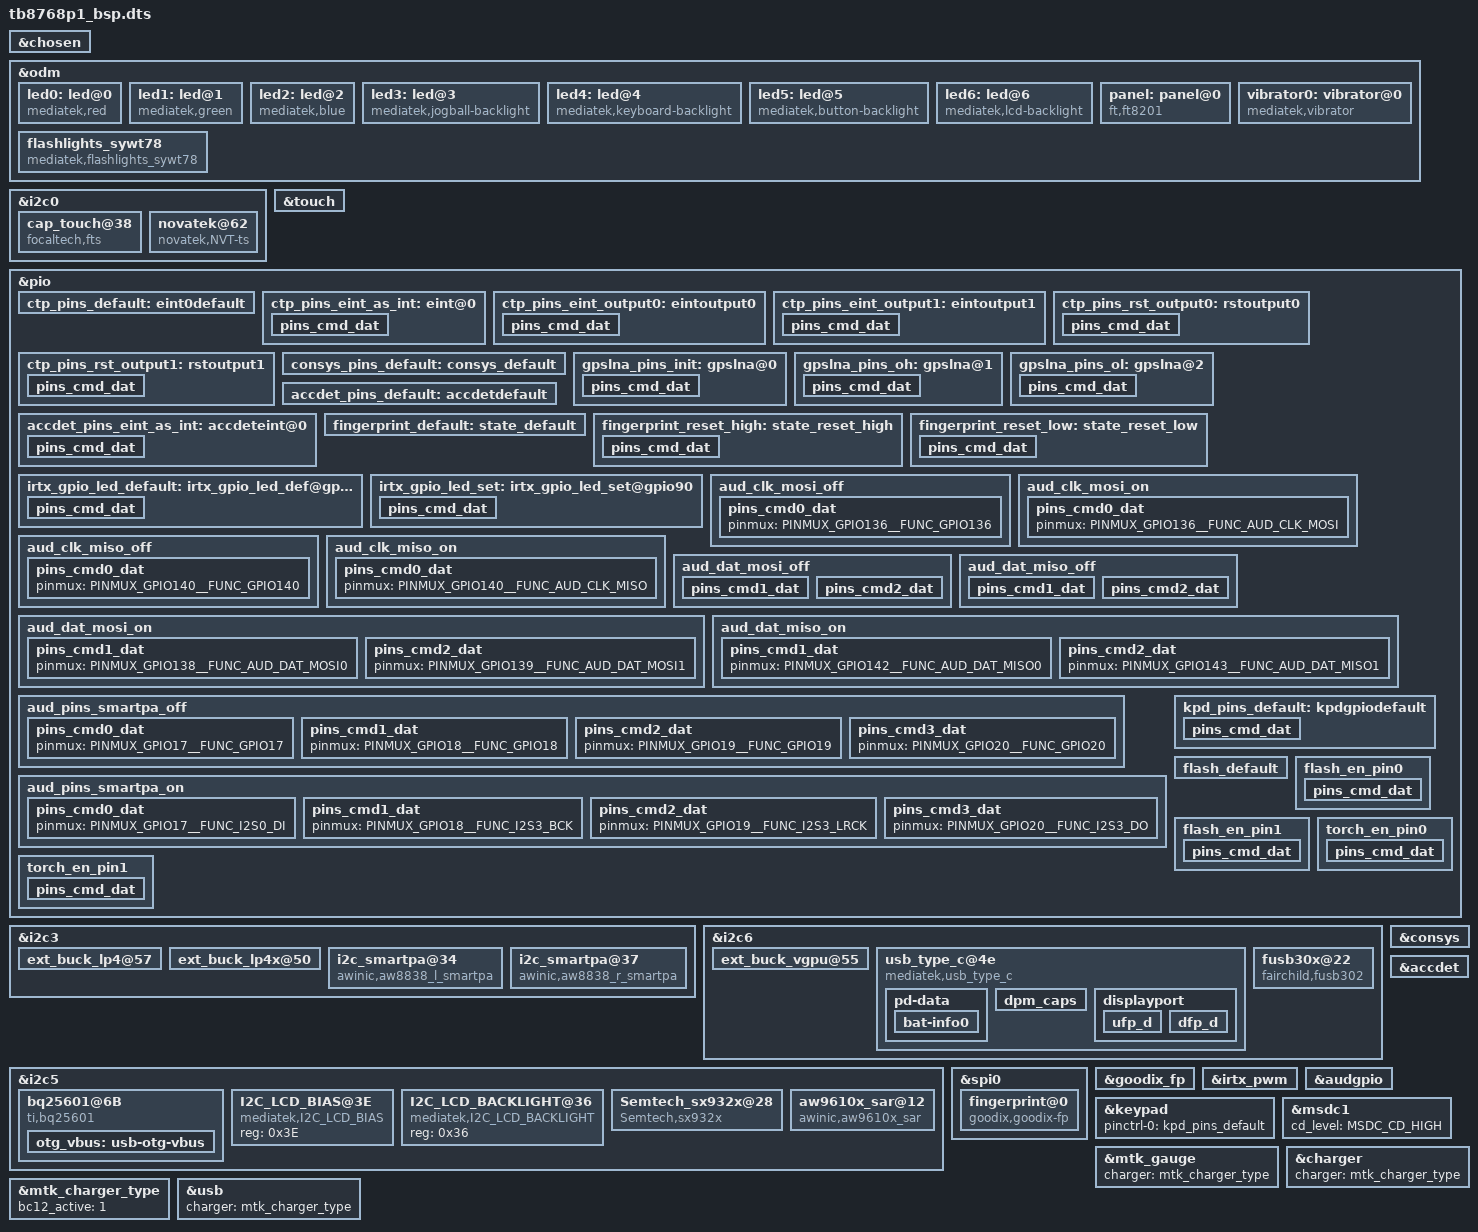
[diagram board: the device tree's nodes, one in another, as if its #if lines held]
// SPDX-License-Identifier: GPL-2.0+
/*
 * Copyright (c) 2019 MediaTek Inc.
 *
 */

#include <dt-bindings/interrupt-controller/arm-gic.h>
#include <dt-bindings/interrupt-controller/irq.h>
#include <dt-bindings/pinctrl/mt6765-pinfunc.h>
#include <dt-bindings/clock/mt6765-clk.h>
#include <dt-bindings/mmc/mt6765-msdc.h>

/dts-v1/;
/plugin/;

/* chosen */
&chosen {

	/* fpga may has no lk, we need to specify display info here */
	/* fb buffer is reserved using this dts by memory node above */
	atag,videolfb-fb_base_h = <0x0>;
	atag,videolfb-fb_base_l = <0x5e605000>;
	atag,videolfb-islcmfound = <1>;
	/* because no lk, so lcm is not inited */
	atag,videolfb-islcm_inited = <0>;
	atag,videolfb-fps= <6000>;
	atag,videolfb-vramSize= <0x017bb000>;
	atag,videolfb-lcmname= "ft8201_wxga_vdo_incell_boe";
};

&odm {
	led0:led@0 {
		compatible = "mediatek,red";
		led_mode = <0>;
		data = <1>;
		pwm_config = <0 0 0 0 0>;
	};
	led1:led@1 {
		compatible = "mediatek,green";
		led_mode = <0>;
		data = <1>;
		pwm_config = <0 0 0 0 0>;
	};
	led2:led@2 {
		compatible = "mediatek,blue";
		led_mode = <0>;
		data = <1>;
		pwm_config = <0 0 0 0 0>;
	};
	led3:led@3 {
		compatible = "mediatek,jogball-backlight";
		led_mode = <0>;
		data = <1>;
		pwm_config = <0 0 0 0 0>;
	};
	led4:led@4 {
		compatible = "mediatek,keyboard-backlight";
		led_mode = <0>;
		data = <1>;
		pwm_config = <0 0 0 0 0>;
	};
	led5:led@5 {
		compatible = "mediatek,button-backlight";
		led_mode = <0>;
		data = <1>;
		pwm_config = <0 0 0 0 0>;
	};
	led6:led@6 {
		compatible = "mediatek,lcd-backlight";
		led_mode = <4>;
		data = <1>;
		pwm_config = <0 3 0 0 0>;
	};
	panel: panel@0 {
		compatible = "ft,ft8201";
		gpio_lcd_rst = <&pio 45 0>;
		gpio_lcd_bl_en = <&pio 154 0>;
		gpio_lcd_bias_enp = <&pio 168 0>;
		gpio_lcd_bias_enn = <&pio 173 0>;
		gpio_tp_rst = <&pio 174 0>;
		status = "okay";
	};
	vibrator0:vibrator@0 {
		compatible = "mediatek,vibrator";
		vib_timer = <25>;
		vib_limit = <9>;
		vib_vol= <9>;
	};
};

/*
&pio {
	lcd_disp_pwm: lcd_disp_pwm {
		pins_cmd_dat {
			pinmux = <PINMUX_GPIO43__FUNC_DISP_PWM>;
		};
	};

	lcd_disp_pwm_gpio: lcd_disp_pwm_gpio {
		pins_cmd_dat {
			pinmux = <PINMUX_GPIO43__FUNC_GPIO43>;
			output-low;
		};
	};
};
*/

&i2c0 {
	cap_touch@38 {
		compatible = "focaltech,fts";
		reg = < 0x38 > ;
		status = "okay" ;
		focaltech,display-coords =  <0 0 800 1280>;
		interrupt-parent = <&pio>;
		interrupts = <0 0x2>;
		focaltech,reset-gpio = <&pio 174 0x01>; 
		focaltech,irq-gpio = <&pio 0 0x02>;
		focaltech,max-touch-number = <10>;
		
	};
	
	novatek@62 {
		compatible = "novatek,NVT-ts" ;
		reg = < 0x62 > ;
		novatek,irq-gpio = <&pio 0 0x2001>;
		status = "okay" ;
	};
};
/* TOUCH start */
&touch {
	tpd-resolution = <800 1280>;
	use-tpd-button = <0>;
	tpd-key-num = <3>;
	//tpd-key-local= <139 172 158 0>;
	//tpd-key-dim-local = <90 883 100 40 230
	//			 883 100 40 370 883 100 40 0 0 0 0>;
	tpd-max-touch-num = <10>;
	tpd-filter-enable = <0>;
	tpd-filter-pixel-density = <106>;
	tpd-filter-custom-prameters = <0 0 0 0 0 0 0 0 0 0 0 0>;
	tpd-filter-custom-speed = <0 0 0>;
	pinctrl-names = "default", "state_eint_as_int", "state_eint_output0",
		"state_eint_output1", "state_rst_output0", "state_rst_output1";
	pinctrl-0 = <&ctp_pins_default>;
	pinctrl-1 = <&ctp_pins_eint_as_int>;
	pinctrl-2 = <&ctp_pins_eint_output0>;
	pinctrl-3 = <&ctp_pins_eint_output1>;
	pinctrl-4 = <&ctp_pins_rst_output0>;
	pinctrl-5 = <&ctp_pins_rst_output1>;
	status = "okay";
};
&pio {
	ctp_pins_default: eint0default {
	};
	ctp_pins_eint_as_int: eint@0 {
		pins_cmd_dat {
			pinmux = <PINMUX_GPIO0__FUNC_GPIO0>;
			slew-rate = <0>;
			bias-disable;
		};
	};
	ctp_pins_eint_output0: eintoutput0 {
		pins_cmd_dat {
			pinmux = <PINMUX_GPIO0__FUNC_GPIO0>;
			slew-rate = <1>;
			output-low;
		};
	};
	ctp_pins_eint_output1: eintoutput1 {
		pins_cmd_dat {
			pinmux = <PINMUX_GPIO0__FUNC_GPIO0>;
			slew-rate = <1>;
			output-high;
		};
	};
	ctp_pins_rst_output0: rstoutput0 {
		pins_cmd_dat {
			pinmux = <PINMUX_GPIO174__FUNC_GPIO174>;
			slew-rate = <1>;
			output-low;
		};
	};
	ctp_pins_rst_output1: rstoutput1 {
		pins_cmd_dat {
			pinmux = <PINMUX_GPIO174__FUNC_GPIO174>;
			slew-rate = <1>;
			output-high;
		};
	};
};
/* TOUCH end */

&i2c3 {
	ext_buck_lp4@57 {
		regulator-name ="ext_buck_vdd2";
		regulator-min-microvolt = <300000>;
		regulator-max-microvolt = <1300000>;
		vsel_pin = <0>;
	};

	ext_buck_lp4x@50 {
		regulator-name ="ext_buck_vddq";
		regulator-min-microvolt = <300000>;
		regulator-max-microvolt = <1300000>;
		vsel_pin = <1>;
	};
	i2c_smartpa@34 {
		compatible = "awinic,aw8838_l_smartpa";
		reg = <0x34>;
		reset-gpio = <&pio 153 0>;
		status = "okay";
	};
	i2c_smartpa@37 {
		compatible = "awinic,aw8838_r_smartpa";
		reg = <0x37>;
		reset-gpio = <&pio 150 0>;
		status = "okay";
	};
};

&i2c6 {
	ext_buck_vgpu@55 {
		regulator-name ="ext_buck_vgpu";
		regulator-min-microvolt = <300000>;
		regulator-max-microvolt = <1300000>;
		vsel_pin = <2>;
	};

	/*aw87519@58 {
		compatible = "awinic,aw87519_left";
		reg = <0x58>;
		reset-gpio = <&pio 174 0>;
		status = "okay";
	};*/
	usb_type_c@4e {
		compatible = "mediatek,usb_type_c";
		reg = <0x4e>;
		charger = <&mtk_charger_type>;
		tcpc-dual,supported_modes = <0>; /* 0: dfp/ufp, */
						 /* 1: dfp, 2: ufp */
		rt-tcpc,name = "type_c_port0"; /* tcpc_device's name */
		rt-tcpc,role_def = <4>; /* 0: SNK Only, 1: SRC Only, 2: DRP, */
					/* 3: Try.SRC, 4: Try.SNK */
		rt-tcpc,rp_level = <0>; /* 0: Default, 1: 1.5, 2: 3.0 */
		rt-tcpc,vconn_supply  = <1>;  /* 0: Never, 1: Always, */
					      /* 2: EMarkOnly, 3: StartOnly */
#if (CONFIG_MTK_GAUGE_VERSION == 30)
		rt-tcpc,notifier_supply_num = <3>;
#else
		rt-tcpc,notifier_supply_num = <2>;
#endif
		rt1711pd,intr_gpio = <&pio 8 0x0>;
		rt1711pd,intr_gpio_num = <8>;
		pd-data {
			pd,vid = <0x29cf>;
			pd,pid = <0x1711>;
			pd,source-cap-ext = <0x171129cf 0x00000000 0x00000000
					     0x00000000 0x00000000 0x02000000>;
			pd,mfrs = "RichtekTCPC";

			/*
			 *	VSAFE5V = 0, MAX_POWER = 1, CUSTOM = 2,
			 *	MAX_POWER_LV = 0x21, MAX_POWER_LVIC = 0x31
			 *	MAX_POWER_HV = 0x41, MAX_POWER_HVIC = 0x51
			 */
			pd,charging_policy= <0x31>;

			/*
			 * Fixed 5V, 500 mA <0x00019032>
			 * Fixed 5V, 1A <0x00019064>
			 * Fixed 5V, 2A <0x000190c8>
			 * Fixed 5V, 3A <0x0001912c>
			 * Fixed 9V, 500 mA <0x0002d032>
			 * Fixed 9V, 1A <0x0002d064>
			 * Fixed 9V, 2A <0x0002d0c8>
			 * Fixed 9V, 3A <0x0002d12c>
			 * Variable 5-9V, 1A <0x8642d064>
			 * Variable 5-9V, 2A <0x8642d0c8>
			 * Variable 5-9V, 3A <0x8642d12c>
			 * PPS 3V~5.9V, 3A <0xC0761E3C>
			 */
			pd,source-pdo-size = <1>;
			pd,source-pdo-data = <0x00019032>;
			pd,sink-pdo-size = <1>;
			pd,sink-pdo-data = <0x000190c8>;

			/*
			 * No DP, host + device
			 *	pd,id-vdo-size = <3>;
			 *	pd,id-vdo-data = <0xd10029cf 0x0 0x17110000>;
			 * With DP
			 *	pd,id-vdo-size = <3>;
			 *	pd,id-vdo-data = <0xd60029cf 0x0 0x17110000
			 */

			pd,id-vdo-size = <3>;
			pd,id-vdo-data = <0xd10029cf 0x0 0x17110000>;

			bat,nr = <1>;
			pd,country_nr = <0>;

			bat-info0 {
				bat,vid = <0x29cf>;
				bat,pid = <0x1711>;
				bat,mfrs = "bat1";
				bat,design_cap = <3000>;
			};

			//bat-info1 {
			//	bat,vid = <0x8abc>;
			//	bat,pid = <0x5234>;
			//	bat,mfrs = "bat2";
			//	bat,design_cap = <4000>;
			//};

			//country0 {
			//	pd,country_code = <0x5457>;
			//	pd,country_len = <2>; /* max len = 26 */
			//	pd,country_data = <0xff 0xff>;
			//};

			//country1 {
			//	pd,country_code = <0x5553>;
			//	pd,country_len = <3>; /* max len = 26 */
			//	pd,country_data = <0xf1 0xf2 0xf3>;
			//};
		};
		dpm_caps {
			local_dr_power;
			local_dr_data;
			//local_ext_power;
			local_usb_comm;
			//local_usb_suspend;
			//local_high_cap;
			//local_give_back;
			local_no_suspend;
			local_vconn_supply;

			//attemp_discover_cable_dfp;
			attemp_enter_dp_mode;
			attemp_discover_cable;
			attemp_discover_id;

			/* 0: disable, 1: prefer_snk, 2: prefer_src */
			pr_check = <0>;
			//pr_reject_as_source;
			//pr_reject_as_sink;
			//pr_check_gp_source;
			//pr_check_gp_sink;

			/* 0: disable, 1: prefer_ufp, 2: prefer_dfp */
			dr_check = <0>;
			//dr_reject_as_dfp;
			//dr_reject_as_ufp;
		};
		displayport {
			/* connection type = "both", "ufp_d", "dfp_d" */
			1st_connection = "dfp_d";
			2nd_connection = "dfp_d";
			signal,dp_v13;
			//signal,dp_gen2;
			usbr20_not_used;
			typec,receptacle;
			ufp_d {
				//pin_assignment,mode_a;
				//pin_assignment,mode_b;
				//pin_assignment,mode_c;
				//pin_assignment,mode_d;
				//pin_assignment,mode_e;
			};
			dfp_d {
				/* Only support mode C & D */
				//pin_assignment,mode_a;
				//pin_assignment,mode_b;
				pin_assignment,mode_c;
				pin_assignment,mode_d;
				pin_assignment,mode_e;
				pin_assignment,mode_f;
			};
		};
	};
	fusb30x@22 {
		status = "ok";
		compatible = "fairchild,fusb302";
		reg = <0x22>;
		interrupt-parent = <&pio>;
		interrupts = <8 0x2>;
		fairchild,int_n = <&pio 8 0>;
	};
};
/* TOUCH start */
/*
&touch {
	tpd-resolution = <1200 1920>;
	use-tpd-button = <0>;
	tpd-key-num = <3>;
	tpd-key-local= <139 172 158 0>;
	tpd-key-dim-local = <90 883 100 40 230
				 883 100 40 370 883 100 40 0 0 0 0>;
	tpd-max-touch-num = <10>;
	tpd-filter-enable = <0>;
	tpd-filter-pixel-density = <106>;
	tpd-filter-custom-prameters = <0 0 0 0 0 0 0 0 0 0 0 0>;
	tpd-filter-custom-speed = <0 0 0>;
	pinctrl-names = "default", "state_eint_as_int", "state_eint_output0",
		"state_eint_output1", "state_rst_output0", "state_rst_output1";
	pinctrl-0 = <&ctp_pins_default>;
	pinctrl-1 = <&ctp_pins_eint_as_int>;
	pinctrl-2 = <&ctp_pins_eint_output0>;
	pinctrl-3 = <&ctp_pins_eint_output1>;
	pinctrl-4 = <&ctp_pins_rst_output0>;
	pinctrl-5 = <&ctp_pins_rst_output1>;
	status = "okay";
};
&pio {
	ctp_pins_default: eint0default {
	};
	ctp_pins_eint_as_int: eint@0 {
		pins_cmd_dat {
			pinmux = <PINMUX_GPIO10__FUNC_GPIO10>;
			slew-rate = <0>;
			bias-disable;
		};
	};
	ctp_pins_eint_output0: eintoutput0 {
		pins_cmd_dat {
			pinmux = <PINMUX_GPIO10__FUNC_GPIO10>;
			slew-rate = <1>;
			output-low;
		};
	};
	ctp_pins_eint_output1: eintoutput1 {
		pins_cmd_dat {
			pinmux = <PINMUX_GPIO10__FUNC_GPIO10>;
			slew-rate = <1>;
			output-high;
		};
	};
	ctp_pins_rst_output0: rstoutput0 {
		pins_cmd_dat {
			pinmux = <PINMUX_GPIO172__FUNC_GPIO172>;
			slew-rate = <1>;
			output-low;
		};
	};
	ctp_pins_rst_output1: rstoutput1 {
		pins_cmd_dat {
			pinmux = <PINMUX_GPIO172__FUNC_GPIO172>;
			slew-rate = <1>;
			output-high;
		};
	};
};
*/
/* TOUCH end */

&i2c5 {
	bq25601@6B {
		status = "okay";
		compatible = "ti,bq25601";
		reg = <0x6B>;

		charger_name = "primary_chg";

		ti,bq2560x,usb-vlim = <4600>;
		ti,bq2560x,usb-ilim = <500>;
		ti,bq2560x,usb-vreg = <4400>;
		ti,bq2560x,usb-ichg = <500>;
		ti,bq2560x,precharge-current = <256>;
		ti,bq2560x,termination-current = <180>;
		ti,bq2560x,boost-voltage = <4998>;
		ti,bq2560x,boost-current = <1200>;
		ti,bq2560x,enable_term;
		ti,bq2560x,stat-pin-ctrl = <3>;
		ti,bq2560x,vac-ovp-threshold = <6500>;
		ti,bq2560x,otg-discharge-gpio = <&pio 24 0x0>;

		otg_vbus: usb-otg-vbus {
			regulator-compatible = "usb-otg-vbus";
			regulator-name = "usb-otg-vbus";
			regulator-min-microvolt = <5000000>;
			regulator-max-microvolt = <5000000>;
		};
	};
	I2C_LCD_BIAS@3E {
		compatible = "mediatek,I2C_LCD_BIAS" ;
		reg = <0x3E> ;
		status = "okay" ;
	};
	I2C_LCD_BACKLIGHT@36 {
		compatible = "mediatek,I2C_LCD_BACKLIGHT" ;
		reg = <0x36> ;
		status = "okay" ;
	};
	/* LCT_P502 modify by jiangqianwen in 202010 start */
 	Semtech_sx932x@28 {
 		compatible = "Semtech,sx932x";
 		reg = <0x28>;
 		interrupt-parent = <&pio>;
 		interrupts = <9 0>;
 
 		Semtech,nirq-gpio = <&pio 9 0x00>;
 		status = "ok";	/**/
 		Semtech,reg-num = <40>; /* total registers number to initialize*/
        Semtech,reg-init  = /bits/ 8 < 
                                 0x10 0x16
                                 0x11 0x20
                                 0X14 0X00
                                 0X15 0X00
                                 0x20 0x20
                                 0x23 0x00
                                 0x24 0xAF
                                 0x26 0x00
                                 0x27 0xAF
                                 0x28 0x3D /*PH0 to CS0 input*/
                                 0x29 0x37
                                 0x2A 0x1F /*PH2 CS2-input,CS1-dync,CS0-HZ*/
                                 0x2B 0x3F
                                 0x2C 0x12
                                 0x2D 0x0B
                                 0x30 0x13
                                 0x31 0x13
                                 0x32 0x20
                                 0x33 0x20
                                 0x34 0x0C
                                 0x35 0x00
                                 0x36 0x0F
                                 0x37 0x16
                                 0x40 0x00
                                 0x41 0x00
                                 0x42 0x11
                                 0x43 0x04
                                 0x44 0x00
                                 0x45 0x05
                                 0x46 0x00
                                 0x47 0x00
                                 0x48 0x00
                                 0x49 0x00
                                 0x4A 0x00
                                 0x4B 0x00
                                 0x4C 0x00
                                 0x05 0x70
                                 0x06 0x00
                                 0x07 0x80
                                 0x11 0x27>;
 
	};

	aw9610x_sar@12 {
				compatible = "awinic,aw9610x_sar";
				reg = <0x12>;
				irq-gpio = <&pio 9 0>;
				chip_name = "AW96103";
				aw9610x,using-firmware;
				status = "okay";
			};
/* LCT_P502 modify by jiangqianwen in 202010 end */
};

/* CONSYS GPIO standardization */
&pio {
	consys_pins_default: consys_default {
	};
	gpslna_pins_init: gpslna@0 {
		pins_cmd_dat {
			pinmux = <PINMUX_GPIO91__FUNC_GPIO91>;
			slew-rate = <0>;
			bias-disable;
			output-low;
		};
	};
	gpslna_pins_oh: gpslna@1 {
		pins_cmd_dat {
			pinmux = <PINMUX_GPIO91__FUNC_GPIO91>;
			slew-rate = <1>;
			output-high;
		};
	};
	gpslna_pins_ol: gpslna@2 {
		pins_cmd_dat {
			pinmux = <PINMUX_GPIO91__FUNC_GPIO91>;
			slew-rate = <1>;
			output-low;
		};
	};
};
&consys {
	pinctrl-names = "default", "gps_lna_state_init",
		"gps_lna_state_oh", "gps_lna_state_ol";
	pinctrl-0 = <&consys_pins_default>;
	pinctrl-1 = <&gpslna_pins_init>;
	pinctrl-2 = <&gpslna_pins_oh>;
	pinctrl-3 = <&gpslna_pins_ol>;
	status = "okay";
};
/* CONSYS end */

/* accdet start */
&accdet {
	accdet-mic-vol = <7>;
	headset-mode-setting = <0x500 0x500 1 0x1f0 0x800 0x800 0x20 0x44>;
	accdet-plugout-debounce = <1>;
	accdet-mic-mode = <1>;
	headset-eint-level-pol = <8>;
	headset-three-key-threshold = <0 80 220 400>;
	headset-three-key-threshold-CDD = <0 121 192 600>;
	headset-four-key-threshold = <0 58 121 192 400>;
	pinctrl-names = "default", "state_eint_as_int";
	pinctrl-0 = <&accdet_pins_default>;
	pinctrl-1 = <&accdet_pins_eint_as_int>;
	status = "okay";
};
&pio {
	accdet_pins_default: accdetdefault {
	};
	accdet_pins_eint_as_int: accdeteint@0 {
		pins_cmd_dat {
			pinmux = <PINMUX_GPIO9__FUNC_GPIO9>;
			slew-rate = <0>;
			bias-disable;
		};
	};
};
/* accdet end */

/* FINGERPRINT start */
&spi0 {
	#address-cells = <1>;
	#size-cells = <0>;
	fingerprint@0 {
		compatible = "goodix,goodix-fp";
		reg = <0>;
		spi-max-frequency = <8000000>;
		netlink-event = <30>;
		status = "okay";
	};
};

&goodix_fp {
	pinctrl-names = "default", "reset_high", "reset_low";
	pinctrl-0 = <&fingerprint_default>;
	pinctrl-1 = <&fingerprint_reset_high>;
	pinctrl-2 = <&fingerprint_reset_low>;
	status = "okay";
};

&pio {
	fingerprint_default: state_default {
	};
	fingerprint_reset_high: state_reset_high {
		pins_cmd_dat {
			pinmux = <PINMUX_GPIO172__FUNC_GPIO172>;
			slew-rate = <1>;
			output-high;
		};
	};
	fingerprint_reset_low: state_reset_low {
		pins_cmd_dat {
			pinmux = <PINMUX_GPIO172__FUNC_GPIO172>;
			slew-rate = <1>;
			output-low;
		};
	};
};
/* FINGERPRINT end */

/* IRTX GPIO end */
&irtx_pwm {
	pinctrl-names = "irtx_gpio_led_default", "irtx_gpio_led_set";
	pinctrl-0 = <&irtx_gpio_led_default>;
	pinctrl-1 = <&irtx_gpio_led_set>;
	status = "okay";
};
&pio {
	irtx_gpio_led_default:irtx_gpio_led_def@gpio90 {
		pins_cmd_dat {
			pinmux = <PINMUX_GPIO90__FUNC_GPIO90>;
			slew-rate = <1>;
			bias-disable;
			output-low;
			input-schmitt-enable = <0>;
		};
	};

	irtx_gpio_led_set:irtx_gpio_led_set@gpio90 {
		pins_cmd_dat {
			pinmux = <PINMUX_GPIO90__FUNC_PWM0>;
			slew-rate = <1>;
			output-high;
		};
	};
};
/* IRTX GPIO Settings -End */

/* AUDIO GPIO standardization */
&audgpio {
	pinctrl-names = "aud_clk_mosi_off",
			"aud_clk_mosi_on",
			"aud_clk_miso_off",
			"aud_clk_miso_on",
			"aud_dat_mosi_off",
			"aud_dat_mosi_on",
			"aud_dat_miso_off",
			"aud_dat_miso_on",
			"aud_smartpa_off",
			"aud_smartpa_on";
	pinctrl-0 = <&aud_clk_mosi_off>;
	pinctrl-1 = <&aud_clk_mosi_on>;
	pinctrl-2 = <&aud_clk_miso_off>;
	pinctrl-3 = <&aud_clk_miso_on>;
	pinctrl-4 = <&aud_dat_mosi_off>;
	pinctrl-5 = <&aud_dat_mosi_on>;
	pinctrl-6 = <&aud_dat_miso_off>;
	pinctrl-7 = <&aud_dat_miso_on>;
	pinctrl-8 = <&aud_pins_smartpa_off>;
	pinctrl-9 = <&aud_pins_smartpa_on>;
	status = "okay";
};

&pio {
	aud_clk_mosi_off: aud_clk_mosi_off {
		pins_cmd0_dat {
			pinmux = <PINMUX_GPIO136__FUNC_GPIO136>;
		};
	};

	aud_clk_mosi_on: aud_clk_mosi_on {
		pins_cmd0_dat {
			pinmux = <PINMUX_GPIO136__FUNC_AUD_CLK_MOSI>;
		};
	};

	aud_clk_miso_off: aud_clk_miso_off {
		pins_cmd0_dat {
			pinmux = <PINMUX_GPIO140__FUNC_GPIO140>;
		};
	};

	aud_clk_miso_on: aud_clk_miso_on {
		pins_cmd0_dat {
			pinmux = <PINMUX_GPIO140__FUNC_AUD_CLK_MISO>;
		};
	};

	aud_dat_mosi_off: aud_dat_mosi_off {
		pins_cmd1_dat {
			pinmux = <PINMUX_GPIO138__FUNC_GPIO138>;
			input-enable;
			slew-rate = <0>;
			bias-disable;
		};
		pins_cmd2_dat {
			pinmux = <PINMUX_GPIO139__FUNC_GPIO139>;
			input-enable;
			slew-rate = <0>;
			bias-disable;
		};
	};

	aud_dat_mosi_on: aud_dat_mosi_on {
		pins_cmd1_dat {
			pinmux = <PINMUX_GPIO138__FUNC_AUD_DAT_MOSI0>;
		};
		pins_cmd2_dat {
			pinmux = <PINMUX_GPIO139__FUNC_AUD_DAT_MOSI1>;
		};
	};

	aud_dat_miso_off: aud_dat_miso_off {
		pins_cmd1_dat {
			pinmux = <PINMUX_GPIO142__FUNC_GPIO142>;
			input-enable;
			slew-rate = <0>;
			bias-disable;
		};
		pins_cmd2_dat {
			pinmux = <PINMUX_GPIO143__FUNC_GPIO143>;
			input-enable;
			slew-rate = <0>;
			bias-disable;
		};
	};

	aud_dat_miso_on: aud_dat_miso_on {
		pins_cmd1_dat {
			pinmux = <PINMUX_GPIO142__FUNC_AUD_DAT_MISO0>;
		};
		pins_cmd2_dat {
			pinmux = <PINMUX_GPIO143__FUNC_AUD_DAT_MISO1>;
		};
	};

	aud_pins_smartpa_off: aud_pins_smartpa_off {
		pins_cmd0_dat {
			pinmux = <PINMUX_GPIO17__FUNC_GPIO17>;
		};
		pins_cmd1_dat {
			pinmux = <PINMUX_GPIO18__FUNC_GPIO18>;
		};
		pins_cmd2_dat {
			pinmux = <PINMUX_GPIO19__FUNC_GPIO19>;
		};
		pins_cmd3_dat {
			pinmux = <PINMUX_GPIO20__FUNC_GPIO20>;
		};
	};

	aud_pins_smartpa_on: aud_pins_smartpa_on {
		pins_cmd0_dat {
			pinmux = <PINMUX_GPIO17__FUNC_I2S0_DI>;
		};
		pins_cmd1_dat {
			pinmux = <PINMUX_GPIO18__FUNC_I2S3_BCK>;
		};
		pins_cmd2_dat {
			pinmux = <PINMUX_GPIO19__FUNC_I2S3_LRCK>;
		};
		pins_cmd3_dat {
			pinmux = <PINMUX_GPIO20__FUNC_I2S3_DO>;
		};
	};
};
/* AUDIO end */

&keypad {
	pinctrl-names = "default";
	pinctrl-0 = <&kpd_pins_default>;
};

&pio {
	kpd_pins_default: kpdgpiodefault {
		pins_cmd_dat {
			pinmux = <PINMUX_GPIO93__FUNC_KPCOL0>;
			bias-pull-up = <MTK_PUPD_SET_R1R0_10>;
			output-low;
			input-schmitt-enable;
		};
	};
};

/* FLASHLIGHT GPIO standardization */
&odm {
	flashlights_sywt78: flashlights_sywt78 {
		compatible = "mediatek,flashlights_sywt78";
		pinctrl-names = "default",
				"flash_low",
				"flash_high",
				"torch_low",
				"torch_high";

		pinctrl-0 = <&flash_default>;
		pinctrl-1 = <&flash_en_pin0>;
		pinctrl-2 = <&flash_en_pin1>;
		pinctrl-3 = <&torch_en_pin0>;
		pinctrl-4 = <&torch_en_pin1>;

		status = "okay";
	};
};

&pio {
	flash_default: flash_default {
	};

	flash_en_pin0: flash_en_pin0 {
		pins_cmd_dat {
			pinmux = <PINMUX_GPIO175__FUNC_GPIO175>;
			slew-rate = <1>;
			output-low;
		};
	};

	flash_en_pin1: flash_en_pin1 {
		pins_cmd_dat {
			pinmux = <PINMUX_GPIO175__FUNC_GPIO175>;
			slew-rate = <1>;
			output-high;
		};
	};

	torch_en_pin0: torch_en_pin0 {
		pins_cmd_dat {
			pinmux = <PINMUX_GPIO176__FUNC_GPIO176>;
			slew-rate = <1>;
			output-low;
		};
	};

	torch_en_pin1: torch_en_pin1 {
		pins_cmd_dat {
			pinmux = <PINMUX_GPIO176__FUNC_GPIO176>;
			slew-rate = <1>;
			output-high;
		};
	};
};
/* FLASHLIGHT end */

#include <tb8768p1_bsp/cust.dtsi>
#include "cust_mt8768_camera.dtsi"

&msdc1 {
	cd_level = /bits/ 8 <MSDC_CD_HIGH>;
};

&mtk_gauge {
	charger = <&mtk_charger_type>;
};

&charger {
	charger = <&mtk_charger_type>;
};

&mtk_charger_type {
	bc12_active = <1>;
};

&usb {
	charger = <&mtk_charger_type>;
};
/*End of this file, DO NOT ADD ANYTHING HERE*/
